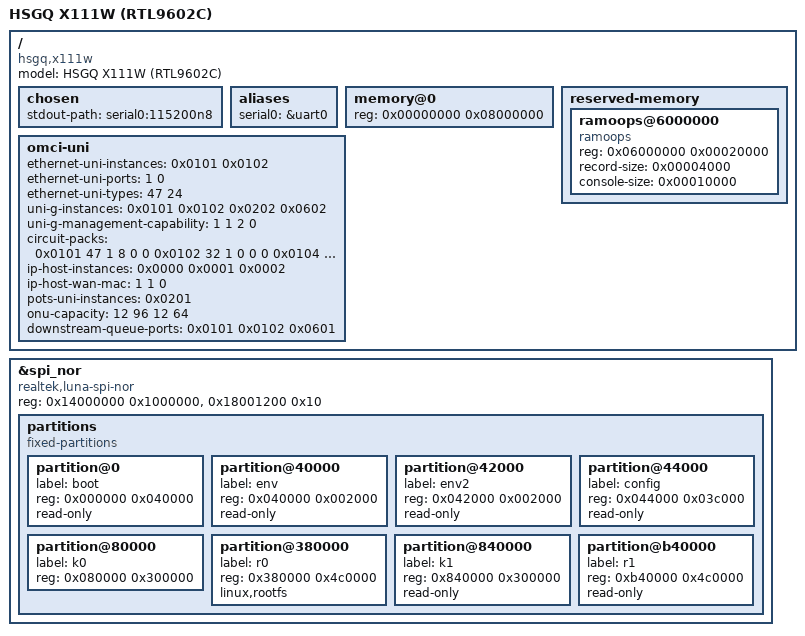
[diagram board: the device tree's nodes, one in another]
// SPDX-License-Identifier: GPL-2.0-or-later
/*
 * HSGQ X111W (X111WF1) GPON ONU — Realtek RTL9602C.
 * 128 MB DDR2, 16 MB SPI-NOR (dual-bank), 1x GE + 1x FE, 2.4 GHz Wi-Fi
 * (RTL8192F, PCIe), GPON MAC RTL8686.
 *
 * Clean-room: board description from observed hardware only.
 */

/dts-v1/;

#include "rtl9602c.dtsi"

/ {
	model = "HSGQ X111W (RTL9602C)";
	compatible = "hsgq,x111w", "realtek,rtl9602c";

	chosen {
		stdout-path = "serial0:115200n8";
		/* bootargs: see luna.dtsi -- the command line is FAMILY
		 * configuration, and this board spelled its own until
		 * 2026-08-27.  The two boards disagreed and only one could be
		 * debugged: without ignore_loglevel this kernel prints nothing
		 * between "Starting kernel" and userspace. */
	};

	aliases {
		serial0 = &uart0;
	};

	memory@0 {
		device_type = "memory";
		reg = <0x00000000 0x08000000>; /* 128 MB DDR2 */
	};

	/*
	 * ★ CRASH TRACE (2026-08-20).  A reserved DRAM window the kernel writes
	 * its dying words into, read back from /sys/fs/pstore on the NEXT boot.
	 *
	 * WHY HERE AND NOT IN A SHARED .dtsi: the address must land in real RAM on
	 * THIS board, and the boards on this target do not share a memory map --
	 * the X111W has one 128 MiB span, the G24W has two with PBO DL holes
	 * between them.  One shared constant would put a panic into unbacked
	 * address space on one of them, and every CONFIG_ symbol would still read
	 * enabled.  It sits beside the memory node above so the two are checked
	 * together; `crash_trace.py --probe` verifies containment and REFUSES a
	 * region that crosses a hole.
	 *
	 * 0x06000000 is mid-DRAM on purpose: the kernel loads low and U-Boot
	 * relocates itself to the top, so neither runs through it.
	 *
	 * NOT `no-map`: pstore/ram memremaps this window, and carving it out of the
	 * linear map is what breaks that.  DRAM contents survive a warm reset, so
	 * this answers a panic or a watchdog bite -- never a power cut.
	 */
	reserved-memory {
		#address-cells = <1>;
		#size-cells = <1>;
		ranges;

		ramoops@6000000 {
			compatible = "ramoops";
			reg = <0x06000000 0x00020000>;	/* 128 KiB */
			record-size  = <0x00004000>;	/*  16 KiB per oops/panic */
			console-size = <0x00010000>;	/*  64 KiB rolling console */
		};
	};

	/*
	 * The UNI panel this board presents over OMCI, MEASURED from its own
	 * stock firmware (omcicli mib get 11/264, 2026-09-12, archived under
	 * results/RTL9602C/HSGQ/X111W/uni-runtime-20260912/).
	 *
	 * TWO Ethernet UNIs here, not four -- this board has one GE and one FE
	 * socket -- and FOUR UNI-Gs, two of which have no Ethernet UNI beside
	 * them.  Its management capabilities are 1, 1, 2 and 0: the value is
	 * not a flag, which is why it is carried per instance.
	 * PhysicalPortId runs 1 then 0 over 0x0101, 0x0102.
	 */
	omci-uni {
		ethernet-uni-instances = /bits/ 16 <0x0101 0x0102>;
		/* The SWITCH PORT each of those instances is, from this board's own PhysicalPortId.  ⚠ WEAKER EVIDENCE than the other two:
		 * no mapper replay has been run here, so this is what stock REPORTS.
		 * ⚠ NEVER COMPUTED: the two Luna boards and the Cortina one run
		 * their port order in OPPOSITE directions, and one numbers its
		 * fourth UNI 0x0401, so no arithmetic on an instance id is
		 * right on more than one board. */
		ethernet-uni-ports = /bits/ 8 <1 0>;
		/* G.988 plug-in type per instance, from this board's own stock:
		 * 0x0101 is the GE port (47) and 0x0102 the FE one (24).  It states
		 * what the UNI IS, so it does not follow the link. */
		ethernet-uni-types = /bits/ 8 <47 24>;
		uni-g-instances = /bits/ 16 <0x0101 0x0102 0x0202 0x0602>;
		uni-g-management-capability = /bits/ 8 <1 1 2 0>;
		/* The equipment slots stock's ME 5/6 report (2026-09-30), from
		 * which the OLT counts 2 Ethernet and 1 POTS port and 24/96
		 * priority queues: instance, plug-in type, ports, priority
		 * queues, T-CONT buffers, schedulers. */
		circuit-packs = /bits/ 16 <
			0x0101  47 1  8  0  0
			0x0102  32 1  0  0  0
			0x0104  24 1  8  0  0
			0x0106  48 1  8  0  0
			0x010b  38 1  0  0  0
			0x0180 248 1 96 12 12>;
		/* ME 134 IP host config data, as stock reports it: three
		 * instances, the first two carrying the WAN MAC. */
		ip-host-instances = /bits/ 16 <0x0000 0x0001 0x0002>;
		ip-host-wan-mac = /bits/ 8 <1 1 0>;
		/* ME 53: stock reports one POTS UNI, and the OLT counts it. */
		pots-uni-instances = /bits/ 16 <0x0201>;
		/* ANI-G #2 and ONU2-G #6/#7/#9 as stock declares them, and its
		 * downstream queue blocks in order. */
		onu-capacity = /bits/ 16 <12 96 12 64>;
		downstream-queue-ports = /bits/ 16 <0x0101 0x0102 0x0601>;
	};
};

&spi_nor {
	/*
	 * Read through the memory-mapped window as before, and erase/program
	 * through the controller's PIO block, so the OpenWrt overlay
	 * (rootfs_data, carved out of r0) persists. Everything outside our own
	 * bank 0 stays read-only.
	 */
	compatible = "realtek,luna-spi-nor";
	reg = <0x14000000 0x1000000>, <0x18001200 0x10>;

	partitions {
		compatible = "fixed-partitions";
		#address-cells = <1>;
		#size-cells = <1>;

		/* Dual-bank layout, matching the vendor mtdparts. */
		partition@0 {
			label = "boot";
			reg = <0x000000 0x040000>;	/* 256K */
			read-only;
		};
		partition@40000 {
			label = "env";
			reg = <0x040000 0x002000>;	/* 8K */
			read-only;
		};
		partition@42000 {
			label = "env2";
			reg = <0x042000 0x002000>;	/* 8K */
			read-only;
		};
		partition@44000 {
			label = "config";
			reg = <0x044000 0x03c000>;	/* 240K (jffs2) */
			read-only;
		};
		partition@80000 {
			label = "k0";
			reg = <0x080000 0x300000>;	/* 3M kernel bank 0 */
		};
		partition@380000 {
			label = "r0";
			reg = <0x380000 0x4c0000>;	/* 4864K rootfs bank 0 */
			/* Mark r0 as the squashfs root: MTD_SPLIT_SQUASHFS_ROOT +
			 * MTD_ROOTFS_ROOT_DEV then set ROOT_DEV (no root= needed from
			 * U-Boot) and carve the rootfs_data overlay child -- without this
			 * the kernel has no root device and VFS panics at mount. Bank 0 is
			 * the flash target. ★ AND IT IS THE ACTIVE ONE SINCE 2026-08-21:
			 * our image was written here and COMMITTED (sw_active=0,
			 * sw_commit=0, read back from the saved U-Boot environment,
			 * then confirmed by /dev/root on /rom = squashfs). The older
			 * wording said "inactive; active bank 1 keeps the live stock"
			 * and was a fact about the unit, not about the design -- it
			 * went stale the day the bank was committed, and a stale
			 * comment in a DTS is read as current by whoever ports the
			 * next board. */
			linux,rootfs;
		};
		partition@840000 {
			label = "k1";
			reg = <0x840000 0x300000>;	/* 3M kernel bank 1 */
			read-only;
		};
		partition@b40000 {
			label = "r1";
			reg = <0xb40000 0x4c0000>;	/* 4864K rootfs bank 1 */
			read-only;
		};
	};
};
